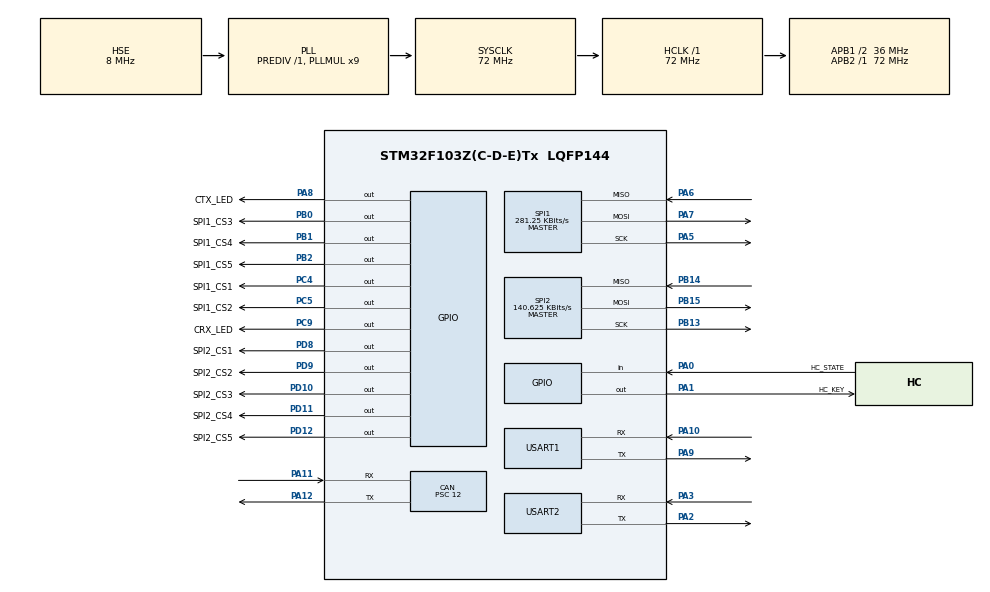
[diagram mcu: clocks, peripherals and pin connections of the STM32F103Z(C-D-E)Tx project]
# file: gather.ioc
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CAN.BS1=CAN_BS1_4TQ
CAN.CalculateBaudRate=499999
CAN.CalculateTimeBit=2000
CAN.CalculateTimeQuantum=333.33333333333337
CAN.Prescaler=12
Mcu.Family=STM32F1
Mcu.Name=STM32F103Z(C-D-E)Tx
Mcu.Package=LQFP144
NVIC.PriorityGroup=NVIC_PRIORITYGROUP_4
NVIC.USART1_IRQn=true\:0\:0\:false\:false\:true\:true\:true\:true
NVIC.USART2_IRQn=true\:0\:0\:false\:false\:true\:true\:true\:true
NVIC.USB_LP_CAN1_RX0_IRQn=true\:0\:0\:false\:false\:true\:true\:true\:true
OSC_IN.Mode=HSE-External-Oscillator
OSC_IN.Signal=RCC_OSC_IN
OSC_OUT.Mode=HSE-External-Oscillator
OSC_OUT.Signal=RCC_OSC_OUT
PA0-WKUP.GPIO_Label=HC_STATE
PA0-WKUP.Signal=GPIO_Input
PA1.GPIO_Label=HC_KEY
PA1.Signal=GPIO_Output
PA10.Mode=Asynchronous
PA10.Signal=USART1_RX
PA11.Mode=CAN_Activate
PA11.Signal=CAN_RX
PA12.Mode=CAN_Activate
PA12.Signal=CAN_TX
PA13.Mode=Serial_Wire
PA13.Signal=SYS_JTMS-SWDIO
PA14.Mode=Serial_Wire
PA14.Signal=SYS_JTCK-SWCLK
PA2.Mode=Asynchronous
PA2.Signal=USART2_TX
PA3.Mode=Asynchronous
PA3.Signal=USART2_RX
PA5.Mode=Full_Duplex_Master
PA5.Signal=SPI1_SCK
PA6.Mode=Full_Duplex_Master
PA6.Signal=SPI1_MISO
PA7.Mode=Full_Duplex_Master
PA7.Signal=SPI1_MOSI
PA8.GPIO_Label=CTX_LED
PA8.PinState=GPIO_PIN_SET
PA8.Signal=GPIO_Output
PA9.Mode=Asynchronous
PA9.Signal=USART1_TX
PB0.GPIO_Label=SPI1_CS3
PB0.GPIO_Speed=GPIO_SPEED_FREQ_LOW
PB0.PinState=GPIO_PIN_RESET
PB0.Signal=GPIO_Output
PB1.GPIO_Label=SPI1_CS4
PB1.GPIO_Speed=GPIO_SPEED_FREQ_LOW
PB1.PinState=GPIO_PIN_RESET
PB1.Signal=GPIO_Output
PB13.Mode=Full_Duplex_Master
PB13.Signal=SPI2_SCK
PB14.Mode=Full_Duplex_Master
PB14.Signal=SPI2_MISO
PB15.Mode=Full_Duplex_Master
PB15.Signal=SPI2_MOSI
PB2.GPIO_Label=SPI1_CS5
PB2.GPIO_Speed=GPIO_SPEED_FREQ_LOW
PB2.PinState=GPIO_PIN_RESET
PB2.Signal=GPIO_Output
PC4.GPIO_Label=SPI1_CS1
PC4.GPIO_Speed=GPIO_SPEED_FREQ_LOW
PC4.PinState=GPIO_PIN_RESET
PC4.Signal=GPIO_Output
PC5.GPIO_Label=SPI1_CS2
PC5.GPIO_Speed=GPIO_SPEED_FREQ_LOW
PC5.PinState=GPIO_PIN_RESET
PC5.Signal=GPIO_Output
PC9.GPIO_Label=CRX_LED
PC9.PinState=GPIO_PIN_RESET
PC9.Signal=GPIO_Output
PD10.GPIO_Label=SPI2_CS3
PD10.Signal=GPIO_Output
PD11.GPIO_Label=SPI2_CS4
PD11.Signal=GPIO_Output
PD12.GPIO_Label=SPI2_CS5
PD12.Signal=GPIO_Output
PD8.GPIO_Label=SPI2_CS1
PD8.Signal=GPIO_Output
PD9.GPIO_Label=SPI2_CS2
PD9.Signal=GPIO_Output
ProjectManager.HeapSize=0x400
ProjectManager.StackSize=0x800
ProjectManager.TargetToolchain=MDK-ARM V5.32
RCC.AHBFreq_Value=72000000
RCC.APB1CLKDivider=RCC_HCLK_DIV2
RCC.APB1Freq_Value=36000000
RCC.APB1TimFreq_Value=72000000
RCC.APB2Freq_Value=72000000
RCC.APB2TimFreq_Value=72000000
RCC.HCLKFreq_Value=72000000
RCC.PLLMUL=RCC_PLL_MUL9
RCC.PLLSourceVirtual=RCC_PLLSOURCE_HSE
RCC.SYSCLKFreq_VALUE=72000000
RCC.SYSCLKSource=RCC_SYSCLKSOURCE_PLLCLK
RCC.USBFreq_Value=72000000
SPI1.BaudRatePrescaler=SPI_BAUDRATEPRESCALER_256
SPI1.CLKPhase=SPI_PHASE_2EDGE
SPI1.CalculateBaudRate=281.25 KBits/s
SPI1.DataSize=SPI_DATASIZE_16BIT
SPI1.Direction=SPI_DIRECTION_2LINES
SPI1.Mode=SPI_MODE_MASTER
SPI1.VirtualType=VM_MASTER
SPI2.BaudRatePrescaler=SPI_BAUDRATEPRESCALER_256
SPI2.CLKPhase=SPI_PHASE_2EDGE
SPI2.CalculateBaudRate=140.625 KBits/s
SPI2.DataSize=SPI_DATASIZE_16BIT
SPI2.Direction=SPI_DIRECTION_2LINES
SPI2.Mode=SPI_MODE_MASTER
SPI2.VirtualType=VM_MASTER
USART1.VirtualMode=VM_ASYNC
USART2.VirtualMode=VM_ASYNC
board=custom

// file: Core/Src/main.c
/* USER CODE BEGIN Header */
/**
 ******************************************************************************
 * @file           : main.c
 * @brief          : Main program body
 ******************************************************************************
 * @attention
 *
 * Copyright (c) 2024 STMicroelectronics.
 * All rights reserved.
 *
 * This software is licensed under terms that can be found in the LICENSE file
 * in the root directory of this software component.
 * If no LICENSE file comes with this software, it is provided AS-IS.
 *
 ******************************************************************************
 */
/* USER CODE END Header */
#include "main.h"
#include "can.h"
#include "spi.h"
#include "usart.h"
#include "gpio.h"

/* USER CODE BEGIN Includes */
#include "stdio.h"
/* USER CODE END Includes */

/* USER CODE BEGIN PD */
uint8_t UART_RDATA;
/* USER CODE END PD */

void SystemClock_Config(void);

/* USER CODE BEGIN 0 */
int fputc(int ch, FILE *f)
{
  uint8_t temp[1] = {ch};
  HAL_UART_Transmit(&huart2, temp, 1, 2);
  // HAL_UART_Transmit(&huart2, temp, 1, 2);
  return ch;
}
/* USER CODE END 0 */

int main(void)
{

  /* MCU Configuration--------------------------------------------------------*/

  /* Reset of all peripherals, Initializes the Flash interface and the Systick. */
  HAL_Init();

  /* Configure the system clock */
  SystemClock_Config();

  /* Initialize all configured peripherals */
  MX_GPIO_Init();
  MX_CAN_Init();
  MX_USART1_UART_Init();
  MX_USART2_UART_Init();
  MX_SPI2_Init();
  MX_SPI1_Init();
  /* USER CODE BEGIN 2 */

  HAL_GPIO_WritePin(GPIOA, CTX_LED_Pin, GPIO_PIN_RESET);
  HAL_Delay(1000);
  HAL_GPIO_WritePin(GPIOA, CTX_LED_Pin,  GPIO_PIN_SET);
  printf("ZERO reset successfully!\r\n");
  Angle_Reset();

  /* USER CODE END 2 */

  /* Infinite loop */
  while (1)
  {

    /* USER CODE BEGIN 3 */
    Read_B();
    HAL_Delay(100);
    		  HAL_GPIO_TogglePin(GPIOC, CRX_LED_Pin);
    //		  HAL_Delay(1000);
  }
  /* USER CODE END 3 */
}

void SystemClock_Config(void)
{
  RCC_OscInitTypeDef RCC_OscInitStruct = {0};
  RCC_ClkInitTypeDef RCC_ClkInitStruct = {0};

  /** Initializes the RCC Oscillators according to the specified parameters
  * in the RCC_OscInitTypeDef structure.
  */
  RCC_OscInitStruct.OscillatorType = RCC_OSCILLATORTYPE_HSE;
  RCC_OscInitStruct.HSEState = RCC_HSE_ON;
  RCC_OscInitStruct.HSEPredivValue = RCC_HSE_PREDIV_DIV1;
  RCC_OscInitStruct.HSIState = RCC_HSI_ON;
  RCC_OscInitStruct.PLL.PLLState = RCC_PLL_ON;
  RCC_OscInitStruct.PLL.PLLSource = RCC_PLLSOURCE_HSE;
  RCC_OscInitStruct.PLL.PLLMUL = RCC_PLL_MUL9;
  if (HAL_RCC_OscConfig(&RCC_OscInitStruct) != HAL_OK)
  {
    Error_Handler();
  }

  /** Initializes the CPU, AHB and APB buses clocks
  */
  RCC_ClkInitStruct.ClockType = RCC_CLOCKTYPE_HCLK|RCC_CLOCKTYPE_SYSCLK
                              |RCC_CLOCKTYPE_PCLK1|RCC_CLOCKTYPE_PCLK2;
  RCC_ClkInitStruct.SYSCLKSource = RCC_SYSCLKSOURCE_PLLCLK;
  RCC_ClkInitStruct.AHBCLKDivider = RCC_SYSCLK_DIV1;
  RCC_ClkInitStruct.APB1CLKDivider = RCC_HCLK_DIV2;
  RCC_ClkInitStruct.APB2CLKDivider = RCC_HCLK_DIV1;

  if (HAL_RCC_ClockConfig(&RCC_ClkInitStruct, FLASH_LATENCY_2) != HAL_OK)
  {
    Error_Handler();
  }
}

void Error_Handler(void)
{
  __disable_irq();
  while (1)
  {
  }
}
